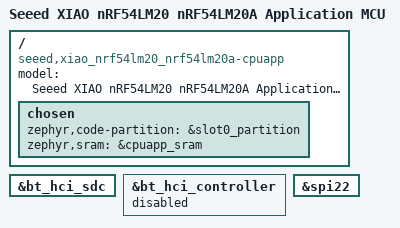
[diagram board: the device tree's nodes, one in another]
/*
 * Copyright (c) 2025 Seeed Technology Co., Ltd.
 *
 * SPDX-License-Identifier: Apache-2.0
 */

/dts-v1/;

#include "nrf54lm20a_cpuapp_common.dtsi"

/ {
	compatible = "seeed,xiao_nrf54lm20_nrf54lm20a-cpuapp";
	model = "Seeed XIAO nRF54LM20 nRF54LM20A Application MCU";

	chosen {
		zephyr,code-partition = &slot0_partition;
		zephyr,sram = &cpuapp_sram;
	};
};

&bt_hci_sdc {
	status = "okay";
};

&bt_hci_controller {
	status = "disabled";
};

/* Get a node label for wi-fi spi to use in shield files */
wifi_spi: &spi22 {};
